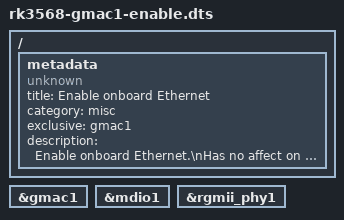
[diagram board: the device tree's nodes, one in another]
/dts-v1/;
/plugin/;

/ {
	metadata {
		title = "Enable onboard Ethernet";
		compatible = "unknown";
		category = "misc";
		exclusive = "gmac1";
		description = "Enable onboard Ethernet.\nHas no affect on external Ethernet (for example USB adapter).";
	};

	fragment@0 {
		target = <&gmac1>;

		__overlay__ {
			status = "okay";
		};
	};

	fragment@1 {
		target = <&mdio1>;

		__overlay__ {
			status = "okay";
		};
	};

	fragment@2 {
		target = <&rgmii_phy1>;

		__overlay__ {
			status = "okay";
		};
	};
};
